AUTOSAR XML (schema 4-2-2)
package /ComponentTypes
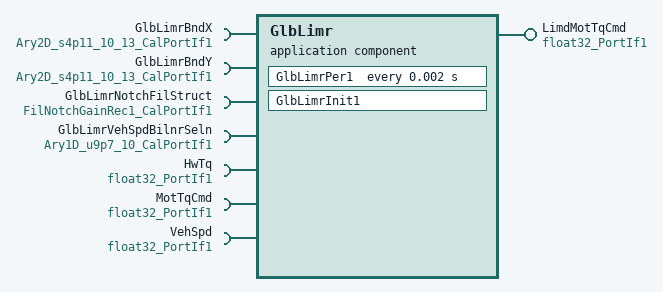
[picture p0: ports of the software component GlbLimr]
  application sw component type GlbLimr
    provide port LimdMotTqCmd: nonqueued-sender-com-spec{data-element=Val, init-value=0}, provided-interface=float32_PortIf1
    7 x require port:
      GlbLimrBndX: parameter-require-com-spec{init-value=10 x [-20480, -10240, -8192, -6144, -4096, -2048, 0, 2048, 4096, 6144, 8192, 10240, 20480], parameter=Ary2D}, required-interface=Ary2D_s4p11_10_13_CalPortIf1
      GlbLimrBndY: parameter-require-com-spec{init-value=[[-11754, -11754, -10774, -4114, -1959, -196, 1567, 3918, 7836, 17631, 18022, 18022, 18022], [-11754, -11754, -9795, -1959, -784, 196, 784, 1175, 5877, 12537, 15672, 18022, 18022], [-11754, -7836, -3918, -1959, -196, 0, 1175, 2938, 3526, 6269, 18022, 18022, 18022], [-11754, -5877, -4506, 0, 196, 588, 784, 980, 2938, 5093, 7836, 18022, 18022], [0, 0, 0, 392, 588, 588, 784, 2938, 3330, 4114, 5877, 5877, 5877], [0, 784, 784, 784, 784, 784, 784, 2547, 2938, 3526, 5877, 5877, 5877], [0, 784, 784, 784, 784, 784, 784, 2547, 2938, 3526, 5877, 5877, 5877], [0, 784, 784, 784, 784, 784, 784, 2547, 2938, 3526, 5877, 5877, 5877], [0, 784, 784, 784, 784, 784, 784, 2547, 2938, 3526, 5877, 5877, 5877], [0, 784, 784, 784, 784, 784, 784, 2547, 2938, 3526, 5877, 5877, 5877]], parameter=Ary2D}, required-interface=Ary2D_s4p11_10_13_CalPortIf1
      GlbLimrNotchFilStruct: parameter-require-com-spec{init-value=fields=[FilGainB0:2.6297, FilGainB1:-4.75311, FilGainB2:2.20752, FilGainA1:-0.2362, FilGainA2:-0.6796], parameter=Rec}, required-interface=FilNotchGainRec1_CalPortIf1
      GlbLimrVehSpdBilnrSeln: parameter-require-com-spec{init-value=[0, 640, 3840, 7680, 10240, 12800, 15360, 19200, 23040, 25600], parameter=Ary1D}, required-interface=Ary1D_u9p7_10_CalPortIf1
      HwTq: nonqueued-receiver-com-spec{data-element=Val, filter=data-filter-type=ALWAYS, init-value=0}, required-interface=float32_PortIf1
      MotTqCmd: nonqueued-receiver-com-spec{data-element=Val, filter=data-filter-type=ALWAYS, init-value=0}, required-interface=float32_PortIf1
      VehSpd: nonqueued-receiver-com-spec{data-element=Val, filter=data-filter-type=ALWAYS, init-value=0}, required-interface=float32_PortIf1
    behavior GlbLimr_InternalBehavior
      ar-typed-per-instance-memorys:
        4 x data, all with sw-calibration-access=READ-ONLY, type=float32:
          GlbLimrNotch1Fil1
          GlbLimrNotch1Fil2
          GlbLimrNotch2Fil1
          GlbLimrNotch2Fil2
      init event GlbLimr_InitEvent: start-on-event=GlbLimrInit1
      timing event TMT_GlbLimrPer1: start-on-event=GlbLimrPer1, period=0.002
      port-api-options:
        enable-take-address=false, error-handling=NO-TRANSFORMER-ERROR-HANDLING, indirect-api=false, port=GlbLimrBndX
        enable-take-address=false, error-handling=NO-TRANSFORMER-ERROR-HANDLING, indirect-api=false, port=GlbLimrBndY
        enable-take-address=false, error-handling=NO-TRANSFORMER-ERROR-HANDLING, indirect-api=false, port=GlbLimrNotchFilStruct
        enable-take-address=false, error-handling=NO-TRANSFORMER-ERROR-HANDLING, indirect-api=false, port=GlbLimrVehSpdBilnrSeln
        enable-take-address=false, error-handling=NO-TRANSFORMER-ERROR-HANDLING, indirect-api=false, port=HwTq
        enable-take-address=false, error-handling=NO-TRANSFORMER-ERROR-HANDLING, indirect-api=false, port=LimdMotTqCmd
        enable-take-address=false, error-handling=NO-TRANSFORMER-ERROR-HANDLING, indirect-api=false, port=MotTqCmd
        enable-take-address=false, error-handling=NO-TRANSFORMER-ERROR-HANDLING, indirect-api=false, port=VehSpd
      runnable GlbLimrInit1
      runnable GlbLimrPer1
        data-receive-point-by-arguments:
          access REC_HwTq_Val: accessed-variable=HwTq.Val
          access REC_MotTqCmd_Val: accessed-variable=MotTqCmd.Val
          access REC_VehSpd_Val: accessed-variable=VehSpd.Val
        data-send-points:
          access SEND_LimdMotTqCmd_Val: accessed-variable=LimdMotTqCmd.Val
  swc implementation GlbLimr_Implementation: behavior=GlbLimr_InternalBehavior
    code-descriptors:
      code Default: artifact-descriptors=autosar-engineering-object={short-label=Default, category=SWSRC}
